# MK80F25615 register map
Vendor: Freescale Semiconductor, Inc.; Series: Kinetis_K; File version: 1.6
CPU: CM4 r0p1, little endian, no MPU, FPU, VTOR, 4 interrupt priority bits
Registers are 32-bit, read-write, reset 0x0 unless marked. A register's access mark holds for its fields unless they carry their own. Offsets are from the block's base; [hi:lo] are bit positions; {n}, {i} and the like mark numbered series; 'fields as' and 'values as' point back to an identical list.

## QuadSPI0 — QuadSPI
Base 0x400DA000; register names take the prefix QuadSPI0_
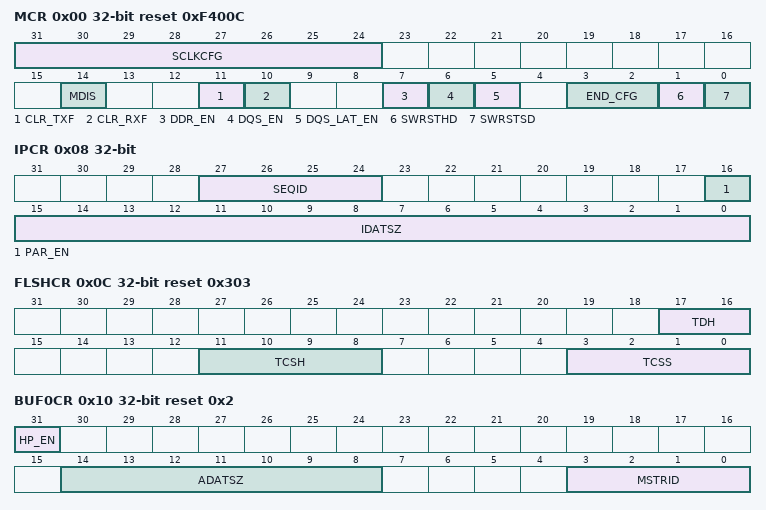
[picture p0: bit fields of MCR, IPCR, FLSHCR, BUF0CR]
0x00 MCR reset 0xF400C — Module Configuration Register
  [31:24] SCLKCFG — Serial Clock Configuration
  [14] MDIS — Module Disable
    0=Enable QuadSPI clocks; 1=Allow external logic to disable QuadSPI clocks
  [11] CLR_TXF wo — Clear TX FIFO/Buffer. Invalidate the TX Buffer content. This is a self-clearing field.
    0=No action; 1=Read and write pointers of the TX Buffer are reset to 0. QSPI_TBSR[TRCTR] is reset to 0.
  [10] CLR_RXF wo — Clear RX FIFO. Invalidate the RX Buffer. This is a self-clearing field.
    0=No action; 1=Read and write pointers of the RX Buffer are reset to 0. QSPI_RBSR[RDBFL] is reset to 0.
  [7] DDR_EN — DDR mode enable:
    0=2x and 4x clocks are disabled for SDR instructions only; 1=2x and 4x clocks are enabled supports both SDR and DDR instruction
  [6] DQS_EN — DQS enable: This field is valid for both SDR and DDR mode
    0=DQS disabled; 1=DQS enabled- When enabled, the incoming data is sampled on both the edges of DQS input when QSPI_MCR[DDR_EN] is set, else, on only one edge when QSPI_MCR[DDR_EN] is 0. The QSPI_SMPR[DDR_SMP] values are ignored.
  [5] DQS_LAT_EN — DQS Latency Enable: This field is valid when latency is included in between read access from FLash in case when QSPI_MCR[DQS_EN] is 1
    0=DQS Latency disabled; 1=DQS feature with latency included enabled
  [3:2] END_CFG — Defines the endianness of the QSPI module.For more details refer to Byte Ordering Endianess
  [1] SWRSTHD — Software reset for AHB domain
    0=No action; 1=AHB domain flops are reset. Does not reset configuration registers. It is advisable to reset both the serial flash domain and AHB domain at the same time. Resetting only one domain might lead to side effects. The software resets need the clock to be running to propagate to the design. The MCR[MDIS] should therefore be set to 0 when the software reset bits are asserted. Also, before they can be deasserted again (by setting MCR[SWRSTHD] to 0), it is recommended to set the MCR[MDIS] bit to 1. Once the software resets have been deasserted, the normal operation can be started by setting the MCR[MDIS] bit to 0.
  [0] SWRSTSD — Software reset for Serial Flash domain
    0=No action; 1=Serial Flash domain flops are reset. Does not reset configuration registers. It is advisable to reset both the serial flash domain and AHB domain at the same time. Resetting only one domain might lead to side effects. The software resets need the clock to be running to propagate to the design. The MCR[MDIS] should therefore be set to 0 when the software reset bits are asserted. Also, before they can be deasserted again (by setting MCR[SWRSTSD] to 0), it is recommended to set the MCR[MDIS] bit to 1. Once the software resets have been deasserted, the normal operation can be started by setting the MCR[MDIS] bit to 0.
0x08 IPCR — IP Configuration Register
  [27:24] SEQID — Points to a sequence in the Look-up-table
  [16] PAR_EN — When set, a transaction to two serial flash devices is triggered in parallel mode
  [15:0] IDATSZ — IP data transfer size: Defines the data transfer size in bytes of the IP command.
0x0C FLSHCR reset 0x303 — Flash Configuration Register
  [17:16] TDH — Serial flash Data In hold time: This helps in meeting the Data In Hold time requirement of a Flash
    0=Data aligned with the posedge of Internal reference clock of QuadSPI; 1=Data aligned with 2x serial flash half clock; 2=Data aligned with 4x serial flash half clock
  [11:8] TCSH — Serial flash CS hold time in terms of serial flash clock cycles
  [3:0] TCSS — Serial flash CS setup time in terms of serial flash clock cycles
0x10 BUF0CR reset 0x2 — Buffer0 Configuration Register
  [31] HP_EN — High Priority Enable: When set, the master associated with this buffer is assigned a priority higher than the rest of the masters
  [14:8] ADATSZ — AHB data transfer size
  [3:0] MSTRID — Master ID: The ID of the AHB master associated with BUFFER0
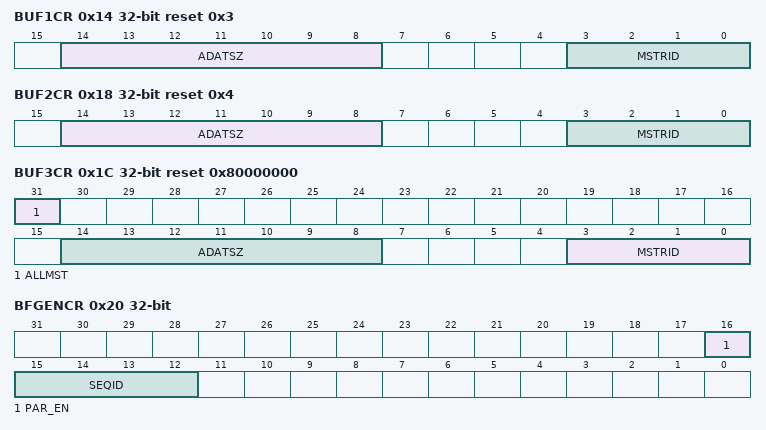
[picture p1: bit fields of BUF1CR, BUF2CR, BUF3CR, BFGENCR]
0x14 BUF1CR reset 0x3 — Buffer1 Configuration Register
  [14:8] ADATSZ — AHB data transfer size
  [3:0] MSTRID — Master ID: The ID of the AHB master associated with BUFFER1
0x18 BUF2CR reset 0x4 — Buffer2 Configuration Register
  [14:8] ADATSZ — AHB data transfer size
  [3:0] MSTRID — Master ID: The ID of the AHB master associated with BUFFER2
0x1C BUF3CR reset 0x80000000 — Buffer3 Configuration Register
  [31] ALLMST — All master enable: When set, buffer3 acts as an all-master buffer
  [14:8] ADATSZ — AHB data transfer size
  [3:0] MSTRID — Master ID: The ID of the AHB master associated with BUFFER3
0x20 BFGENCR — Buffer Generic Configuration Register
  [16] PAR_EN — When set, a transaction to two serial flash devices is triggered in parallel mode
  [15:12] SEQID — Points to a sequence in the Look-up-table
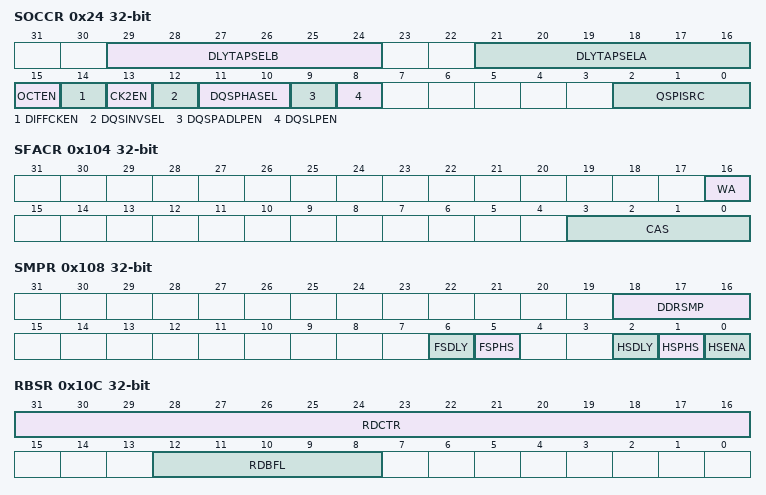
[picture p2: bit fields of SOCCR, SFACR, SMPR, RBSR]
0x24 SOCCR — SOC Configuration Register
  [29:24] DLYTAPSELB — Delay chain tap number selection for QSPI Port B DQS
    {v}=Select {v+1} delay chain tap (v=0..63)
  [21:16] DLYTAPSELA — Delay chain tap number selection for QSPI Port A DQS
    {v}=Select {v+1} delay chain tap (v=0..63)
  [15] OCTEN — Octal data pins enable
    0=QSPI0B_DATAx pins are assigned to QSPI Port B; 1=QSPI0B_DATAx pins are assigned to QSPI Port A
  [14] DIFFCKEN — Differential flash clock pins enable
    0=Differential flash clock is disabled; 1=Differential flash clock is enabled
  [13] CK2EN — Flash CK2 clock pin enable
    0=CK2 flash clock is disabled; 1=CK2 flash clock is enabled
  [12] DQSINVSEL — Select clock source for internal DQS generation
    0=Use 1x internal reference clock for the DQS generation; 1=Use inverse 1x internal reference clock for the DQS generation
  [11:10] DQSPHASEL — Select phase shift for internal DQS generation. These bits are always zero in SDR mode.
    0=No phase shift; 1=Select 45 degree phase shift; 2=Select 90 degree phase shift; 3=Select 135 degree phase shift
  [9] DQSPADLPEN — When this bit is set the internal generated DQS will be sent to the DQS pad first and then looped back to QuadSPI. DQSLPEN should be cleared when this bit is set.
    0=DQS loop back from DQS pad is disabled; 1=DQS loop back from DQS pad is enabled
  [8] DQSLPEN — When this bit is set the internal generated DQS is selected and looped back to QuadSPI, without going to DQS pad. DQSPADLPEN should be cleared when this bit is set.
    0=DQS loop back is disabled; 1=DQS loop back is enabled
  [2:0] QSPISRC — QSPI clock source select
    0=Core/system clock; 1=MCGFLL clock; 2=MCGPLL clock; 3=MCGPLL 2x clock (DDR mode specific); 4=IRC48M clock; 5=OSCERCLK clock; 6=MCGIRCLK clock
{0x30+4i} BUF{i}IND (i=0..2) — Buffer{i} Top Index Register
  [31:3] TPINDX{i} — Top index of buffer {i}.
0x100 SFAR — Serial Flash Address Register
  [31:0] SFADR — Serial Flash Address. The register content is used as byte address for all following IP Commands.
0x104 SFACR — Serial Flash Address Configuration Register
  [16] WA — Word Addressable
    0=Byte addressable serial flash mode; 1=Word (2 byte) addressable serial flash mode
  [3:0] CAS — Column Address Space
0x108 SMPR — Sampling Register
  [18:16] DDRSMP — DDR Sampling point
  [6] FSDLY — Full Speed Delay selection for SDR instructions. Select the delay with respect to the reference edge for the sample point valid for full speed commands:
    0=One clock cycle delay; 1=Two clock cycles delay. This bit is also used in DQS mode and ignored when using non-DQS DDR instructions.
  [5] FSPHS — Full Speed Phase selection for SDR instructions.
    0=Select sampling at non-inverted clock; 1=Select sampling at inverted clock. This bit is also used in DQS mode and ignored when using non-DQS DDR instructions.
  [2] HSDLY — Half Speed Delay selection for SDR instructions.
    0=One clock cycle delay; 1=Two clock cycle delay
  [1] HSPHS — Half Speed Phase selection for SDR instructions.
    0=Select sampling at non-inverted clock; 1=Select sampling at inverted clock
  [0] HSENA — Half Speed serial flash clock Enable
    0=Disable divide by 2 of serial flash clock for half speed commands; 1=Enable divide by 2 of serial flash clock for half speed commands
0x10C RBSR ro — RX Buffer Status Register
  [31:16] RDCTR — Read Counter, indicates how many entries of 4 bytes have been removed from the RX Buffer
  [12:8] RDBFL — RX Buffer Fill Level, indicates how many entries of 4 bytes are still available in the RX Buffer
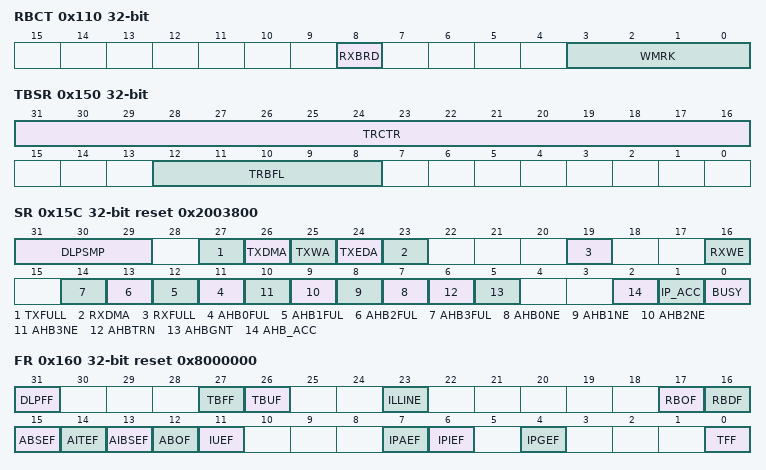
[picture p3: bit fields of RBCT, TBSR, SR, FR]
0x110 RBCT — RX Buffer Control Register
  [8] RXBRD — RX Buffer Readout: This bit specifies the access scheme for the RX Buffer readout.
    0=RX Buffer content is read using the AHB Bus registers QSPI_ARDB0 to QSPI_ARDB15. For details, refer to Exclusive Access to Serial Flash for AHB Commands.; 1=RX Buffer content is read using the IP Bus registers QSPI_RBDR0 to QSPI_RBDR15
  [3:0] WMRK — RX Buffer Watermark: This field determines when the readout action of the RX Buffer is triggered
0x150 TBSR ro — TX Buffer Status Register
  [31:16] TRCTR — Transmit Counter
  [12:8] TRBFL — TX Buffer Fill Level
0x154 TBDR — TX Buffer Data Register
  [31:0] TXDATA — TX Data On write access the data is written into the next available entry of the TX Buffer and the QPSI_TBSR[TRBFL] field is updated accordingly
0x158 TBCT — Tx Buffer Control Register
  [3:0] WMRK — Determines the watermark for the TX Buffer
0x15C SR ro reset 0x2003800 — Status Register
  [31:29] DLPSMP — Data learning pattern sampling point: The sampling point found by the controller with the data learning pattern
  [27] TXFULL — TX Buffer Full: Asserted when no more data can be stored.
  [26] TXDMA
  [25] TXWA — TX Buffer watermark Available
  [24] TXEDA — Tx Buffer Enough Data Available
  [23] RXDMA — RX Buffer DMA: Asserted when RX Buffer read out via DMA is active i.e DMA is requested or running.
  [19] RXFULL — RX Buffer Full: Asserted when the RX Buffer is full, i
  [16] RXWE — RX Buffer Watermark Exceeded: Asserted when the number of valid entries in the RX Buffer exceeds the number given in the QSPI_RBCT[WMRK] field
  [n+11] AHB{n}FUL (n=0..3) — AHB {n} Buffer Full: Asserted when AHB {n} buffer is full.
  [n+7] AHB{n}NE (n=0..3) — AHB {n} Buffer Not Empty: Asserted when AHB {n} buffer contains data.
  [6] AHBTRN — AHB Access Transaction pending: Asserted when there is a pending request on the AHB interface
  [5] AHBGNT — AHB Command priority Granted: Asserted when another module has been granted priority of AHB Commands against IP Commands
  [2] AHB_ACC — AHB Access: Asserted when the transaction currently executed was initiated by AHB bus.
  [1] IP_ACC — IP Access: Asserted when transaction currently executed was initiated by IP bus.
  [0] BUSY — Module Busy: Asserted when module is currently busy handling a transaction to an external flash device
0x160 FR reset 0x8000000 — Flag Register
  [31] DLPFF — Data Learning Pattern Failure Flag: Set when DATA_LEARN instruction was encountered in a sequence but no sampling point was found for the data learning patternin case only 8 bit data learning is requested for non DQS mode
  [27] TBFF — TX Buffer Fill Flag: Before writing to the TX buffer, this bit should be cleared
  [26] TBUF — TX Buffer Underrun Flag: Set when the module tried to pull data although TX Buffer was emptyor the buffer contains less than 128bits of data
  [23] ILLINE — Illegal Instruction Error Flag: Set when an illegal instruction is encountered by the controller in any of the sequences
  [17] RBOF — RX Buffer Overflow Flag: Set when not all the data read from the serial flash device could be pushed into the RX Buffer
  [16] RBDF — RX Buffer Drain Flag: Will be set if the QuadSPI_SR[RXWE] status bit is asserted
  [15] ABSEF — AHB Sequence Error Flag: Set when the execution of an AHB Command is started with a WRITE or WRITE_DDR Command in the sequence pointed to by the QSPI_BUFxCR register
  [14] AITEF — AHB Illegal transaction error flag
  [13] AIBSEF — AHB Illegal Burst Size Error Flag: Set whenever the total burst size(size x beat) of an AHB transaction is greater than the prefetch data size
  [12] ABOF — AHB Buffer Overflow Flag: Set when the size of the AHB access exceeds the size of the AHB buffer
  [11] IUEF — IP Command Usage Error Flag: Set when in parallel flash mode the execution of an IP Command is started with more than one pad enabled and the sequence pointed to by the sequence ID contains a WRITE or a WRITE_DDR command
  [7] IPAEF — IP Command Trigger during AHB Access Error Flag
  [6] IPIEF — IP Command Trigger could not be executed Error Flag
  [4] IPGEF — IP Command Trigger during AHB Grant Error Flag: Set when the following condition occurs: A write access occurs to the QSPI_IPCR[SEQID] field and the QSPI_SR[AHBGNT] bit is set
  [0] TFF — IP Command Transaction Finished Flag: Set when the QuadSPI module has finished a running IP Command
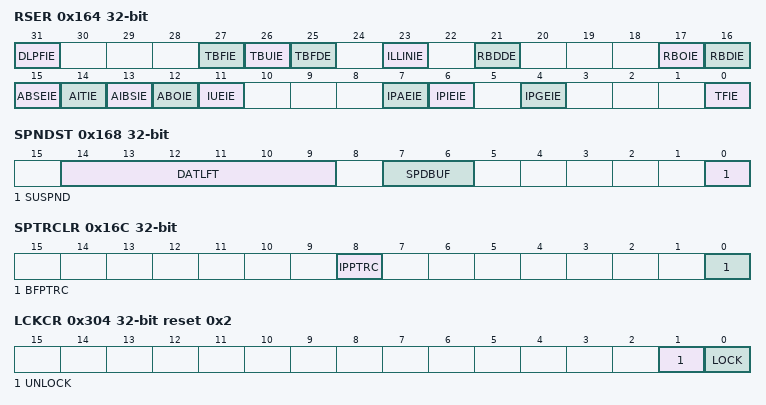
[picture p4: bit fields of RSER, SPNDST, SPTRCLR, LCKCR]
0x164 RSER — Interrupt and DMA Request Select and Enable Register
  [31] DLPFIE — Data Learning Pattern Failure Interrupt enable . Triggered by DLPFF flag in QSPI_FR register
    0=No DLPFF interrupt will be generated; 1=DLPFF interrupt will be generated
  [27] TBFIE — TX Buffer Fill Interrupt Enable
    0=No TBFF interrupt will be generated; 1=TBFF interrupt will be generated
  [26] TBUIE — TX Buffer Underrun Interrupt Enable
    0=No TBUF interrupt will be generated; 1=TBUF interrupt will be generated
  [25] TBFDE — TX Buffer Fill DMA Enable
    0=No DMA request will be generated; 1=DMA request will be generated
  [23] ILLINIE — Illegal Instruction Error Interrupt Enable. Triggered by ILLINE flag in QSPI_FR
    0=No ILLINE interrupt will be generated; 1=ILLINE interrupt will be generated
  [21] RBDDE — RX Buffer Drain DMA Enable: Enables generation of DMA requests for RX Buffer Drain
    values as TBFDE
  [17] RBOIE — RX Buffer Overflow Interrupt Enable
    0=No RBOF interrupt will be generated; 1=RBOF interrupt will be generated
  [16] RBDIE — RX Buffer Drain Interrupt Enable: Enables generation of IRQ requests for RX Buffer Drain
    0=No RBDF interrupt will be generated; 1=RBDF Interrupt will be generated
  [15] ABSEIE — AHB Sequence Error Interrupt Enable: Triggered by ABSEF flags of QSPI_FR
    0=No ABSEF interrupt will be generated; 1=ABSEF interrupt will be generated
  [14] AITIE — AHB Illegal transaction interrupt enable.
    0=No AITEF interrupt will be generated; 1=AITEF interrupt will be generated
  [13] AIBSIE — AHB Illegal Burst Size Interrupt Enable
    0=No AIBSEF interrupt will be generated; 1=AIBSEF interrupt will be generated
  [12] ABOIE — AHB Buffer Overflow Interrupt Enable
    0=No ABOF interrupt will be generated; 1=ABOF interrupt will be generated
  [11] IUEIE — IP Command Usage Error Interrupt Enable
    0=No IUEF interrupt will be generated; 1=IUEF interrupt will be generated
  [7] IPAEIE — IP Command Trigger during AHB Access Error Interrupt Enable
    0=No IPAEF interrupt will be generated; 1=IPAEF interrupt will be generated
  [6] IPIEIE — IP Command Trigger during IP Access Error Interrupt Enable
    0=No IPIEF interrupt will be generated; 1=IPIEF interrupt will be generated
  [4] IPGEIE — IP Command Trigger during AHB Grant Error Interrupt Enable
    0=No IPGEF interrupt will be generated; 1=IPGEF interrupt will be generated
  [0] TFIE — Transaction Finished Interrupt Enable
    0=No TFF interrupt will be generated; 1=TFF interrupt will be generated
0x168 SPNDST ro — Sequence Suspend Status Register
  [14:9] DATLFT — Data left: Provides information about the amount of data left to be read in the suspended sequence
  [7:6] SPDBUF — Suspended Buffer: Provides the suspended buffer number. Valid only when SUSPND is set to 1'b1
  [0] SUSPND — When set, it signifies that a sequence is in suspended state
0x16C SPTRCLR — Sequence Pointer Clear Register
  [8] IPPTRC wo — IP Pointer Clear: 1: Clears the sequence pointer for IP accesses as defined in QuadSPI_IPCR This is a self-clearing field
  [0] BFPTRC wo — Buffer Pointer Clear: 1: Clears the sequence pointer for AHB accesses as defined in QuadSPI_BFGENCR
0x180 SFA1AD reset 0x6FFFFC00 — Serial Flash A1 Top Address
  [31:10] TPADA1 — Top address for Serial Flash A1. In effect, TPADxx is the first location of the next memory.
0x184 SFA2AD reset 0x6FFFFC00 — Serial Flash A2 Top Address
  [31:10] TPADA2 — Top address for Serial Flash A2. In effect, TPxxAD is the first location of the next memory.
0x188 SFB1AD reset 0x6FFFFC00 — Serial Flash B1Top Address
  [31:10] TPADB1 — Top address for Serial Flash B1.In effect, TPxxAD is the first location of the next memory.
0x18C SFB2AD reset 0x6FFFFC00 — Serial Flash B2Top Address
  [31:10] TPADB2 — Top address for Serial Flash B2. In effect, TPxxAD is the first location of the next memory.
0x190 DLPR reset 0xAA553443 — Data Learn Pattern Register
  [31:0] DLPV — Data Learning Pattern Value: This value is used for data learning in DDR and DQS mode
{0x200+4i} RBDR{i} (i=0..15) ro — RX Buffer Data Register
  [31:0] RXDATA
0x300 LUTKEY reset 0x5AF05AF0
  [31:0] KEY — The key to lock or unlock the LUT. The KEY is 0x5AF05AF0. The read value is always 0x5AF05AF0
0x304 LCKCR reset 0x2 — LUT Lock Configuration Register
  [1] UNLOCK — Unlocks the LUT when the following two conditions are met: 1
  [0] LOCK — Locks the LUT when the following condition is met: This register is written just after the LUTKEYLUT Key Register The LUT key register was written with 0x5AF05AF0 key
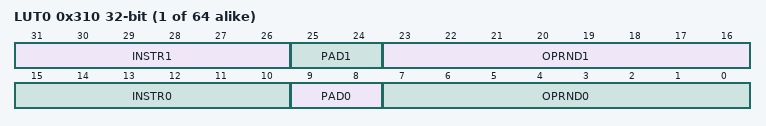
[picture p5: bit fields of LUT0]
{0x310+4i} LUT{i} (i=0..63) — Look-up Table register
  [31:26] INSTR1 — Instruction 1
  [25:24] PAD1 — Pad information for INSTR1.
    0=1 Pad; 1=2 Pads; 2=4 Pads; 3=8 Pads
  [23:16] OPRND1 — Operand for INSTR1.
  [15:10] INSTR0 — Instruction 0
  [9:8] PAD0 — Pad information for INSTR0.
    0=1 Pad; 1=2 Pads; 2=4 Pads; 3=8 Pads
  [7:0] OPRND0 — Operand for INSTR0.
